# STM32F107 register map
File version: 1.2
CPU: CM3 r1p1, little endian, no MPU, no FPU, 4 interrupt priority bits
Registers are 32-bit, read-write, reset 0x0 unless marked. A register's access mark holds for its fields unless they carry their own. Offsets are from the block's base; [hi:lo] are bit positions; {n}, {i} and the like mark numbered series.

## TIM9 — General purpose timer
Base 0x40014C00
Same registers: TIM12 0x40001800
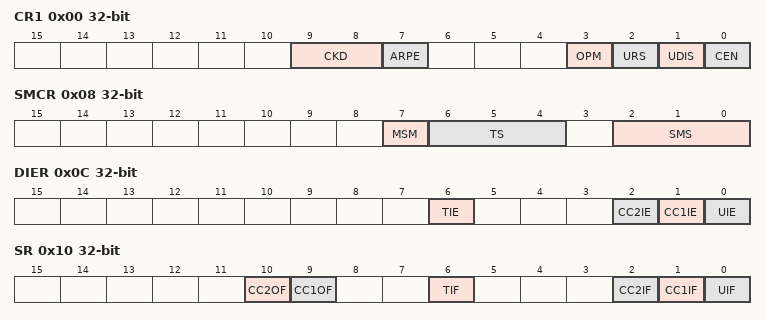
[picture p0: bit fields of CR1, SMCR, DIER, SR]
0x00 CR1 — control register 1
  [9:8] CKD — Clock division
  [7] ARPE — Auto-reload preload enable
  [3] OPM — One-pulse mode
  [2] URS — Update request source
  [1] UDIS — Update disable
  [0] CEN — Counter enable
0x04 CR2 — control register 2
  [6:4] MMS — Master mode selection
0x08 SMCR — slave mode control register
  [7] MSM — Master/Slave mode
  [6:4] TS — Trigger selection
  [2:0] SMS — Slave mode selection
0x0C DIER — DMA/Interrupt enable register
  [6] TIE — Trigger interrupt enable
  [2] CC2IE — Capture/Compare 2 interrupt enable
  [1] CC1IE — Capture/Compare 1 interrupt enable
  [0] UIE — Update interrupt enable
0x10 SR — status register
  [10] CC2OF — Capture/compare 2 overcapture flag
  [9] CC1OF — Capture/Compare 1 overcapture flag
  [6] TIF — Trigger interrupt flag
  [2] CC2IF — Capture/Compare 2 interrupt flag
  [1] CC1IF — Capture/compare 1 interrupt flag
  [0] UIF — Update interrupt flag
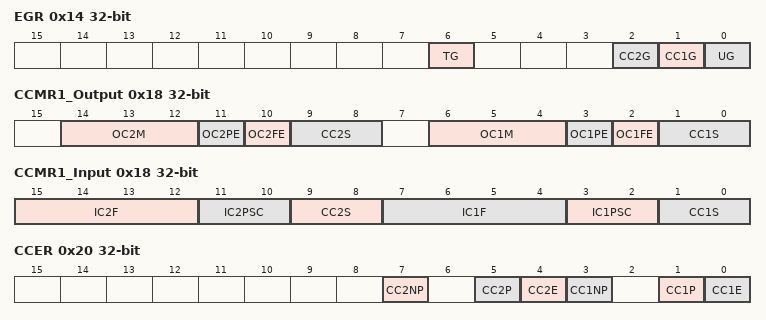
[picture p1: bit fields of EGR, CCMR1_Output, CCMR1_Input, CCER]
0x14 EGR wo — event generation register
  [6] TG — Trigger generation
  [2] CC2G — Capture/compare 2 generation
  [1] CC1G — Capture/compare 1 generation
  [0] UG — Update generation
0x18 CCMR1_Output — capture/compare mode register 1 (output mode)
  [14:12] OC2M — Output Compare 2 mode
  [11] OC2PE — Output Compare 2 preload enable
  [10] OC2FE — Output Compare 2 fast enable
  [9:8] CC2S — Capture/Compare 2 selection
  [6:4] OC1M — Output Compare 1 mode
  [3] OC1PE — Output Compare 1 preload enable
  [2] OC1FE — Output Compare 1 fast enable
  [1:0] CC1S — Capture/Compare 1 selection
0x18 CCMR1_Input (alternate view of CCMR1_Output) — capture/compare mode register 1 (input mode)
  [15:12] IC2F — Input capture 2 filter
  [11:10] IC2PSC — Input capture 2 prescaler
  [9:8] CC2S — Capture/Compare 2 selection
  [7:4] IC1F — Input capture 1 filter
  [3:2] IC1PSC — Input capture 1 prescaler
  [1:0] CC1S — Capture/Compare 1 selection
0x20 CCER — capture/compare enable register
  [7] CC2NP — Capture/Compare 2 output Polarity
  [5] CC2P — Capture/Compare 2 output Polarity
  [4] CC2E — Capture/Compare 2 output enable
  [3] CC1NP — Capture/Compare 1 output Polarity
  [1] CC1P — Capture/Compare 1 output Polarity
  [0] CC1E — Capture/Compare 1 output enable
0x24 CNT — counter
  [15:0] CNT — counter value
0x28 PSC — prescaler
  [15:0] PSC — Prescaler value
0x2C ARR — auto-reload register
  [15:0] ARR — Auto-reload value
0x34 CCR1 — capture/compare register 1
  [15:0] CCR1 — Capture/Compare 1 value
0x38 CCR2 — capture/compare register 2
  [15:0] CCR2 — Capture/Compare 2 value

## USB — Universal serial bus full-speed device interface
Base 0x40005C00
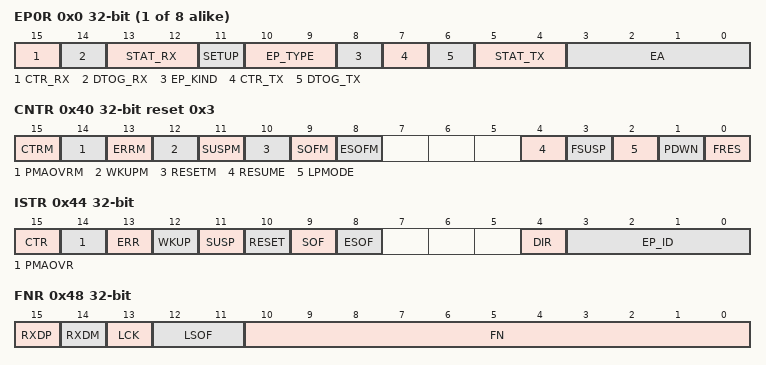
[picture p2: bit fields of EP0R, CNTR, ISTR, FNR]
{0x0+4i} EP{i}R (i=0..7) — endpoint {i} register
  [15] CTR_RX — Correct transfer for reception
  [14] DTOG_RX — Data Toggle, for reception transfers
  [13:12] STAT_RX — Status bits, for reception transfers
  [11] SETUP — Setup transaction completed
  [10:9] EP_TYPE — Endpoint type
  [8] EP_KIND — Endpoint kind
  [7] CTR_TX — Correct Transfer for transmission
  [6] DTOG_TX — Data Toggle, for transmission transfers
  [5:4] STAT_TX — Status bits, for transmission transfers
  [3:0] EA — Endpoint address
0x40 CNTR reset 0x3 — control register
  [15] CTRM — Correct transfer interrupt mask
  [14] PMAOVRM — Packet memory area over / underrun interrupt mask
  [13] ERRM — Error interrupt mask
  [12] WKUPM — Wakeup interrupt mask
  [11] SUSPM — Suspend mode interrupt mask
  [10] RESETM — USB reset interrupt mask
  [9] SOFM — Start of frame interrupt mask
  [8] ESOFM — Expected start of frame interrupt mask
  [4] RESUME — Resume request
  [3] FSUSP — Force suspend
  [2] LPMODE — Low-power mode
  [1] PDWN — Power down
  [0] FRES — Force USB Reset
0x44 ISTR — interrupt status register
  [15] CTR — Correct transfer
  [14] PMAOVR — Packet memory area over / underrun
  [13] ERR — Error
  [12] WKUP — Wakeup
  [11] SUSP — Suspend mode request
  [10] RESET — reset request
  [9] SOF — start of frame
  [8] ESOF — Expected start frame
  [4] DIR — Direction of transaction
  [3:0] EP_ID — Endpoint Identifier
0x48 FNR ro — frame number register
  [15] RXDP — Receive data + line status
  [14] RXDM — Receive data - line status
  [13] LCK — Locked
  [12:11] LSOF — Lost SOF
  [10:0] FN — Frame number
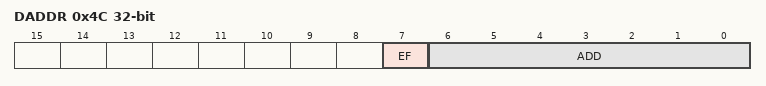
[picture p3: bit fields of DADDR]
0x4C DADDR — device address
  [7] EF — Enable function
  [6:0] ADD — Device address
0x50 BTABLE — Buffer table address
  [15:3] BTABLE — Buffer table

## NVIC — Nested Vectored Interrupt Controller
Base 0xE000E100
0x00 ISER0 — Interrupt Set-Enable Register
  [31:0] SETENA
0x04 ISER1 — Interrupt Set-Enable Register
  [31:0] SETENA
0x80 ICER0 — Interrupt Clear-Enable Register
  [31:0] CLRENA
0x84 ICER1 — Interrupt Clear-Enable Register
  [31:0] CLRENA
0x100 ISPR0 — Interrupt Set-Pending Register
  [31:0] SETPEND
0x104 ISPR1 — Interrupt Set-Pending Register
  [31:0] SETPEND
0x180 ICPR0 — Interrupt Clear-Pending Register
  [31:0] CLRPEND
0x184 ICPR1 — Interrupt Clear-Pending Register
  [31:0] CLRPEND
0x200 IABR0 ro — Interrupt Active Bit Register
  [31:0] ACTIVE
0x204 IABR1 ro — Interrupt Active Bit Register
  [31:0] ACTIVE
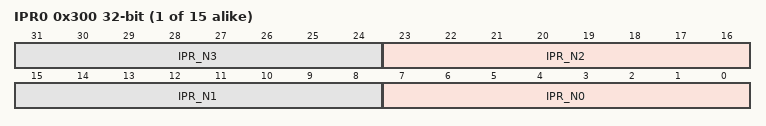
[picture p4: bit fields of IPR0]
{0x300+4i} IPR{i} (i=0..14) — Interrupt Priority Register
  [8n+7:8n] IPR_N{n} (n=0..3)

## MPU — Memory protection unit
Base 0xE000ED90
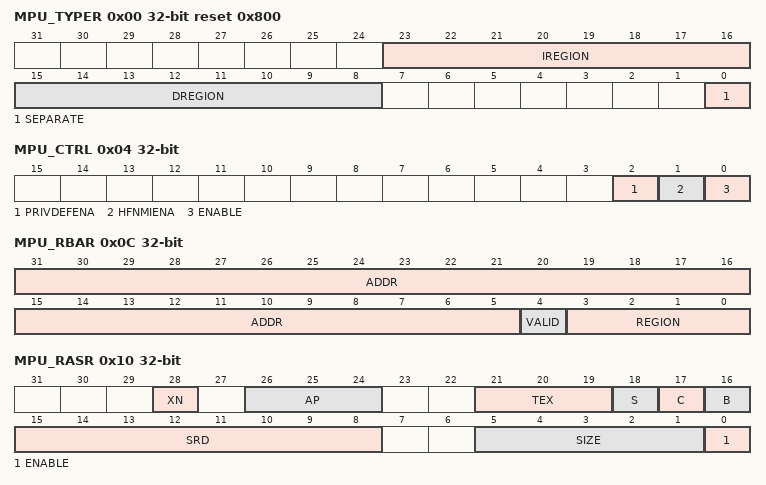
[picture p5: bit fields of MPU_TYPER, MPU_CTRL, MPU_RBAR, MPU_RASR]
0x00 MPU_TYPER ro reset 0x800 — MPU type register
  [23:16] IREGION — Number of MPU instruction regions
  [15:8] DREGION — Number of MPU data regions
  [0] SEPARATE — Separate flag
0x04 MPU_CTRL ro — MPU control register
  [2] PRIVDEFENA — Enable priviliged software access to default memory map
  [1] HFNMIENA — Enables the operation of MPU during hard fault
  [0] ENABLE — Enables the MPU
0x08 MPU_RNR — MPU region number register
  [7:0] REGION — MPU region
0x0C MPU_RBAR — MPU region base address register
  [31:5] ADDR — Region base address field
  [4] VALID — MPU region number valid
  [3:0] REGION — MPU region field
0x10 MPU_RASR — MPU region attribute and size register
  [28] XN — Instruction access disable bit
  [26:24] AP — Access permission
  [21:19] TEX — memory attribute
  [18] S — Shareable memory attribute
  [17] C — memory attribute
  [16] B — memory attribute
  [15:8] SRD — Subregion disable bits
  [5:1] SIZE — Size of the MPU protection region
  [0] ENABLE — Region enable bit.

## SCB_ACTRL — System control block ACTLR
Base 0xE000E008
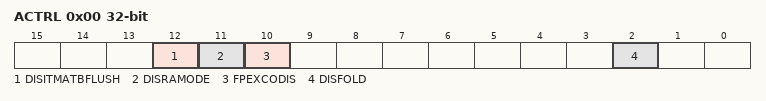
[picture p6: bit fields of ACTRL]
0x00 ACTRL — Auxiliary control register
  [12] DISITMATBFLUSH, [11] DISRAMODE, [10] FPEXCODIS, [2] DISFOLD

## NVIC_STIR — Nested vectored interrupt controller
Base 0xE000EF00
0x00 STIR — Software trigger interrupt register
  [8:0] INTID — Software generated interrupt ID

## STK — SysTick timer
Base 0xE000E010
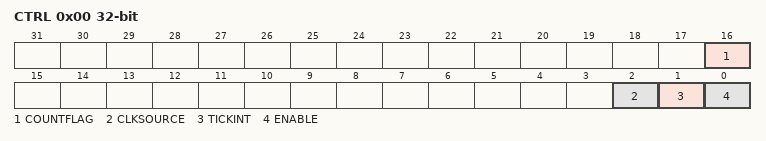
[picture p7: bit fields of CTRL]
0x00 CTRL — SysTick control and status register
  [16] COUNTFLAG
  [2] CLKSOURCE — Clock source selection
  [1] TICKINT — SysTick exception request enable
  [0] ENABLE — Counter enable
0x04 LOAD_ — SysTick reload value register
  [23:0] RELOAD — RELOAD value
0x08 VAL — SysTick current value register
  [23:0] CURRENT — Current counter value
0x0C CALIB — SysTick calibration value register
  [23:0] TENMS — Calibration value
